# PIC18LF4320 register map
Vendor: Microchip
Architecture 18xxxx. Special function registers and configuration words.
Registers are 8-bit, read-write, no defined reset value unless marked. A register's access mark holds for its fields unless they carry their own. Addresses are absolute, and some are shared; only a register's first bit layout is shown; lines under a group give offsets from that group; [hi:lo] are bit positions; {n}, {i} and the like mark numbered series; 'fields as' and 'values as' point back to an identical list; <NAME> marks a mode.

## Further device data
pins=1: MCLR/VPP/RE3; 2: RA0/AN0; 3: RA1/AN1; 4: RA2/AN2/VREF-/CVREF; 5: RA3/AN3/VREF+; 6: RA4/T0CKI/C1OUT; 7: RA5/AN4/SS/LVDIN/C2OUT; 8: RE0/AN5/RD; 9: RE1/AN6/WR; 10: RE2/AN7/CS; 11: VDD; 12: VSS; 13: OSC1/CLKI/RA7; 14: OSC2/CLKO/RA6; 15: RC0/T1OSO/T1CKI; 16: RC1/T1OSI/CCP2; 17: RC2/CCP1/P1A; 18: RC3/SCK/SCL; 19: RD0/PSP0; 20: RD1/PSP1; 21: RD2/PSP2; 22: RD3/PSP3; 23: RC4/SDI/SDA; 24: RC5/SDO; 25: RC6/TX/CK; 26: RC7/RX/DT; 27: RD4/PSP4; 28: RD5/PSP5/P1B; 29: RD6/PSP6/P1C; 30: RD7/PSP7/P1D; 31: VSS; 32: VDD; 33: RB0/AN12/INT0; 34: RB1/AN10/INT1; 35: RB2/AN8/INT2; 36: RB3/AN9/CCP2; 37: RB4/AN11/KBI0; 38: RB5/KBI1/PGM; 39: RB6/KBI2/PGC; 40: RB7/KBI3/PGD

## CONFIG — Configuration words, addresses in ProgramSpace
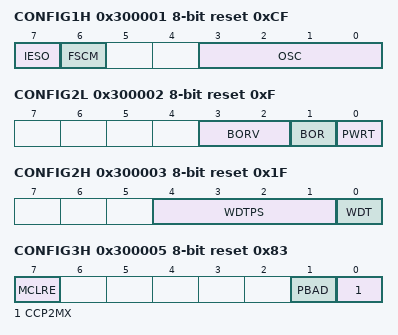
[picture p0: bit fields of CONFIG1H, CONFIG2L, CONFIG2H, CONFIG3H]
0x300001 CONFIG1H reset 0xCF
  [7] IESO — Internal/External Switchover bit
    1=ON (Internal/External Switchover mode enabled); 0=OFF (Internal/External Switchover mode disabled)
  [6] FSCM — Fail-Safe Clock Monitor Enable bit
    1=ON (Fail-Safe Clock Monitor enabled); 0=OFF (Fail-Safe Clock Monitor disabled)
  [3:0] OSC — Oscillator Selection bits
    0b11xx=RC (External RC oscillator, CLKO function on RA6); 9=INTIO1 (Internal RC oscillator, CLKO function on RA6 and port function on RA7); 8=INTIO2 (Internal RC oscillator, port function on RA6 and port function on RA7); 7=RCIO (External RC oscillator, port function on RA6); 6=HSPLL (HS oscillator, PLL enabled (clock frequency = 4 x FOSC1)); 5=ECIO (EC oscillator, port function on RA6); 4=EC (EC oscillator, CLKO function on RA6); 2=HS (HS Oscillator); 1=XT (XT Oscillator); 0=LP (LP Oscillator)
0x300002 CONFIG2L reset 0xF
  [3:2] BORV — Brown-out Reset Voltage bits
    3=VBOR set to 2.0V; 2=VBOR set to 2.7V; 1=VBOR set to 4.2V; 0=VBOR set to 4.5V
  [1] BOR — Brown-out Reset enable bit
    1=ON (Brown-out Reset enabled); 0=OFF (Brown-out Reset disabled)
  [0] PWRT — Power-up Timer enable bit
    1=OFF (PWRT disabled); 0=ON (PWRT enabled)
0x300003 CONFIG2H reset 0x1F
  [4:1] WDTPS — Watchdog Timer Postscale Select bits
    15=1:32768; 14=1:16384; 13=1:8192; 12=1:4096; 11=1:2048; 10=1:1024; 9=1:512; 8=1:256; 7=1:128; 6=1:64; 5=1:32; 4=1:16; 3=1:8; 2=1:4; 1=1:2; 0=1:1
  [0] WDT — Watchdog Timer Enable bit
    1=ON (WDT enabled); 0=OFF (WDT disabled (control is placed on the SWDTEN bit))
0x300005 CONFIG3H reset 0x83
  [7] MCLRE — MCLR Pin Enable bit
    1=ON (MCLR pin enabled; RE3 input pin disabled); 0=OFF (MCLR disabled; RE3 input is enabled in 40-pin devices only (PIC18F4X20))
  [1] PBAD — PORTB A/D Enable bit
    1=ANA (PORTB<4:0> pins are configured as analog input channels on Reset); 0=DIG (PORTB<4:0> pins are configured as digital I/O on Reset)
  [0] CCP2MX — CCP2 MUX bit
    1=ON (CCP2 input/output is multiplexed with RC1); 0=OFF (CCP2 input/output is multiplexed with RB3)
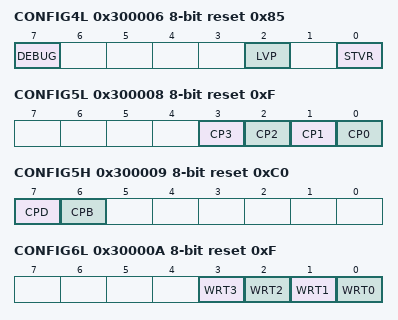
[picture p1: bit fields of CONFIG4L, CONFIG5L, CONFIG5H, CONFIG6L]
0x300006 CONFIG4L reset 0x85
  [7] DEBUG — Background Debugger Enable bit
    1=OFF (Background debugger disabled, RB6 and RB7 configured as general purpose I/O pins); 0=ON (Background debugger enabled, RB6 and RB7 are dedicated to In-Circuit Debug)
  [2] LVP — Single-Supply ICSP Enable bit
    1=ON (Single-Supply ICSP enabled); 0=OFF (Single-Supply ICSP disabled)
  [0] STVR — Stack Full/Underflow Reset Enable bit
    1=ON (Stack full/underflow will cause Reset); 0=OFF (Stack full/underflow will not cause Reset)
0x300008 CONFIG5L reset 0xF
  [3] CP3 — Code Protection bit
    1=OFF (Block 3 (001800-001FFFh) not code-protected); 0=ON (Block 3 (001800-001FFFh) code-protected)
  [2] CP2 — Code Protection bit
    1=OFF (Block 2 (001000-0017FFh) not code-protected); 0=ON (Block 2 (001000-0017FFh) code-protected)
  [1] CP1 — Code Protection bit
    1=OFF (Block 1 (000800-000FFFh) not code-protected); 0=ON (Block 1 (000800-000FFFh) code-protected)
  [0] CP0 — Code Protection bit
    1=OFF (Block 0 (000200-0007FFh) not code-protected); 0=ON (Block 0 (000200-0007FFh) code-protected)
0x300009 CONFIG5H reset 0xC0
  [7] CPD — Data EEPROM Code Protection bit
    1=OFF (Data EEPROM is not code-protected); 0=ON (Data EEPROM is code-protected)
  [6] CPB — Boot Block Code Protection bit
    1=OFF (Boot block (000000-0001FFh) is not code-protected); 0=ON (Boot block (000000-0001FFh) is code-protected)
0x30000A CONFIG6L reset 0xF
  [3] WRT3 — Write Protection bit
    1=OFF (Block 3 (001800-001FFFh) not write-protected); 0=ON (Block 3 (001800-001FFFh) write-protected)
  [2] WRT2 — Write Protection bit
    1=OFF (Block 2 (001000-0017FFh) not write-protected); 0=ON (Block 2 (001000-0017FFh) write-protected)
  [1] WRT1 — Write Protection bit
    1=OFF (Block 1 (000800-000FFFh) not write-protected); 0=ON (Block 1 (000800-000FFFh) write-protected)
  [0] WRT0 — Write Protection bit
    1=OFF (Block 0 (000200-0007FFh) not write-protected); 0=ON (Block 0 (000200-0007FFh) write-protected)
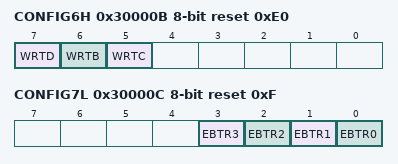
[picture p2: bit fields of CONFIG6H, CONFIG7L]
0x30000B CONFIG6H reset 0xE0
  [7] WRTD — Data EEPROM Write Protection bit
    1=OFF (Data EEPROM is not write-protected); 0=ON (Data EEPROM is write-protected)
  [6] WRTB — Boot Block Write Protection bit
    1=OFF (Boot block (000000-0001FFh) is not write-protected); 0=ON (Boot block (000000-0001FFh) is write-protected)
  [5] WRTC — Configuration Register Write Protection bit
    1=OFF (Configuration registers (300000-3000FFh) are not write-protected); 0=ON (Configuration registers (300000-3000FFh) are write-protected)
0x30000C CONFIG7L reset 0xF
  [3] EBTR3 — Table Read Protection bit
    1=OFF (Block 3 (001800-001FFFh) not protected from table reads executed in other blocks); 0=ON (Block 3 (001800-001FFFh) protected from table reads executed in other blocks)
  [2] EBTR2 — Table Read Protection bit
    1=OFF (Block 2 (001000-0017FFh) not protected from table reads executed in other blocks); 0=ON (Block 2 (001000-0017FFh) protected from table reads executed in other blocks)
  [1] EBTR1 — Table Read Protection bit
    1=OFF (Block 1 (000800-000FFFh) not protected from table reads executed in other blocks); 0=ON (Block 1 (000800-000FFFh) protected from table reads executed in other blocks)
  [0] EBTR0 — Table Read Protection bit
    1=OFF (Block 0 (000200-0007FFh) not protected from table reads executed in other blocks); 0=ON (Block 0 (000200-0007FFh) protected from table reads executed in other blocks)
0x30000D CONFIG7H reset 0x40
  [6] EBTRB — Boot Block Table Read Protection bit
    1=OFF (Boot block (000000-0001FFh) is not protected from table reads executed in other blocks); 0=ON (Boot block (000000-0001FFh) is protected from table reads executed in other blocks)
